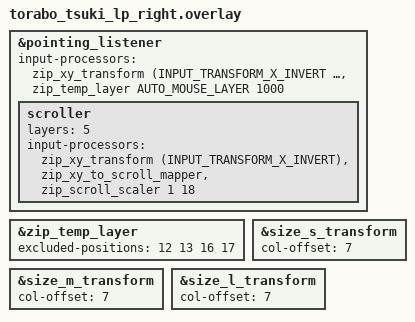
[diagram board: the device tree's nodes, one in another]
#include "torabo_tsuki_lp.dtsi"
#include <input/processors.dtsi>
#include <dt-bindings/zmk/input_transform.h>

/* オートマウスレイヤー: トラックボール操作で有効化する layer_1 */
#define AUTO_MOUSE_LAYER 4

&pointing_listener {
    input-processors =
        <&zip_xy_transform (INPUT_TRANSFORM_X_INVERT | INPUT_TRANSFORM_Y_INVERT)>,
        <&zip_temp_layer AUTO_MOUSE_LAYER 1000>;
};

/* トラックボール操作で layer_1 を一時有効化し、無操作1秒で解除。
 * excluded-positions はクリック系キー(D/F/J/K)。押しても解除しない。
 * ※ 番号は「実行時のアクティブ物理レイアウト」の体系。本機は実行時Sレイアウトで動作しており
 *   (Studioで保存されたアクティブレイアウト設定+position-mapによる変換)、S体系では
 *   D=12 F=13 J=16 K=17 (USBログの position: 16 = J で実測確認済み)。
 *   Lレイアウトで使う場合は 27 28 30 31 33 34 に読み替えが必要。
 * ※ require-prior-idle-ms は付けない: 付けると未活性中のキー入力で起動が延期され続け、
 *   ボールを動かしながらキーを押すと永久に活性化しない(初回活性化を阻害する)ため。 */
&zip_temp_layer {
    excluded-positions = <12 13 16 17>;
};

&size_s_transform {
    col-offset = <7>;
};

&size_m_transform {
    col-offset = <7>;
};

&size_l_transform {
    col-offset = <7>;
};
/* スクロールレイヤー: layer_4が有効な間はボールの動きをスクロールに変換
 * 方向はカーソルと同じ反転を適用。速度は zip_scroll_scaler 1 12 (1/12倍) で調整可 */
&pointing_listener {
    scroller {
        layers = <5>;
        input-processors =
            <&zip_xy_transform (INPUT_TRANSFORM_X_INVERT)>,
            <&zip_xy_to_scroll_mapper>,
            <&zip_scroll_scaler 1 18>;
    };
};
